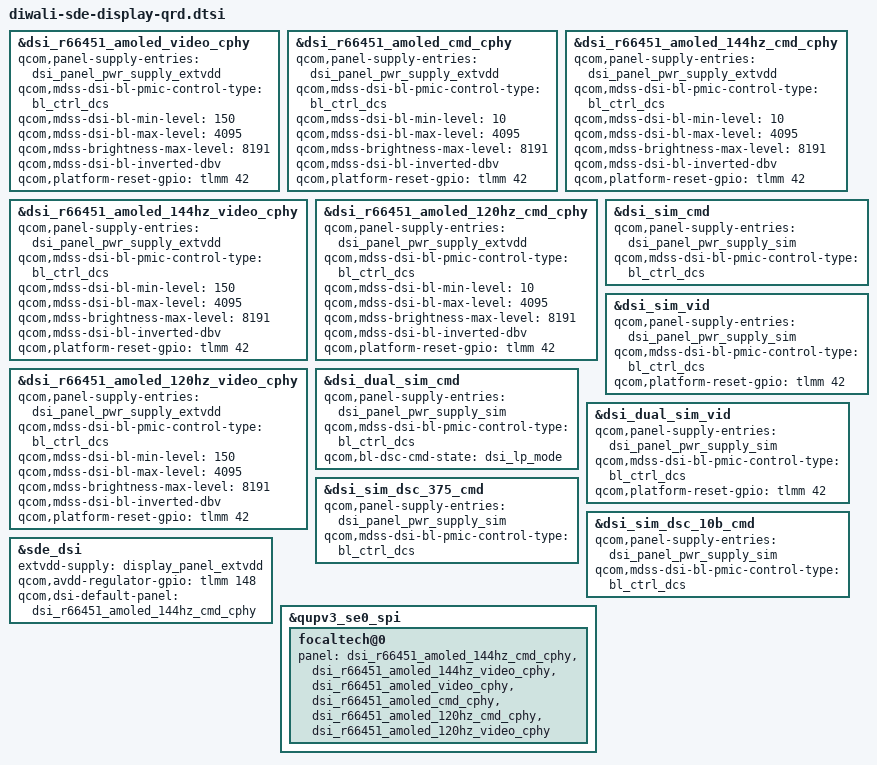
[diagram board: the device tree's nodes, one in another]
#include "diwali-sde-display.dtsi"

&dsi_r66451_amoled_video_cphy {
	qcom,panel-supply-entries = <&dsi_panel_pwr_supply_extvdd>;
	qcom,mdss-dsi-bl-pmic-control-type = "bl_ctrl_dcs";
	qcom,mdss-dsi-bl-min-level = <150>;
	qcom,mdss-dsi-bl-max-level = <4095>;
	qcom,mdss-brightness-max-level = <8191>;
	qcom,mdss-dsi-bl-inverted-dbv;
	qcom,platform-reset-gpio = <&tlmm 42 0>;
};

&dsi_r66451_amoled_cmd_cphy {
	qcom,panel-supply-entries = <&dsi_panel_pwr_supply_extvdd>;
	qcom,mdss-dsi-bl-pmic-control-type = "bl_ctrl_dcs";
	qcom,mdss-dsi-bl-min-level = <10>;
	qcom,mdss-dsi-bl-max-level = <4095>;
	qcom,mdss-brightness-max-level = <8191>;
	qcom,mdss-dsi-bl-inverted-dbv;
	qcom,platform-reset-gpio = <&tlmm 42 0>;
};

&dsi_r66451_amoled_144hz_cmd_cphy {
	qcom,panel-supply-entries = <&dsi_panel_pwr_supply_extvdd>;
	qcom,mdss-dsi-bl-pmic-control-type = "bl_ctrl_dcs";
	qcom,mdss-dsi-bl-min-level = <10>;
	qcom,mdss-dsi-bl-max-level = <4095>;
	qcom,mdss-brightness-max-level = <8191>;
	qcom,mdss-dsi-bl-inverted-dbv;
	qcom,platform-reset-gpio = <&tlmm 42 0>;
};

&dsi_r66451_amoled_144hz_video_cphy {
	qcom,panel-supply-entries = <&dsi_panel_pwr_supply_extvdd>;
	qcom,mdss-dsi-bl-pmic-control-type = "bl_ctrl_dcs";
	qcom,mdss-dsi-bl-min-level = <150>;
	qcom,mdss-dsi-bl-max-level = <4095>;
	qcom,mdss-brightness-max-level = <8191>;
	qcom,mdss-dsi-bl-inverted-dbv;
	qcom,platform-reset-gpio = <&tlmm 42 0>;
};

&dsi_r66451_amoled_120hz_cmd_cphy {
	qcom,panel-supply-entries = <&dsi_panel_pwr_supply_extvdd>;
	qcom,mdss-dsi-bl-pmic-control-type = "bl_ctrl_dcs";
	qcom,mdss-dsi-bl-min-level = <10>;
	qcom,mdss-dsi-bl-max-level = <4095>;
	qcom,mdss-brightness-max-level = <8191>;
	qcom,mdss-dsi-bl-inverted-dbv;
	qcom,platform-reset-gpio = <&tlmm 42 0>;
};

&dsi_r66451_amoled_120hz_video_cphy {
	qcom,panel-supply-entries = <&dsi_panel_pwr_supply_extvdd>;
	qcom,mdss-dsi-bl-pmic-control-type = "bl_ctrl_dcs";
	qcom,mdss-dsi-bl-min-level = <150>;
	qcom,mdss-dsi-bl-max-level = <4095>;
	qcom,mdss-brightness-max-level = <8191>;
	qcom,mdss-dsi-bl-inverted-dbv;
	qcom,platform-reset-gpio = <&tlmm 42 0>;
};

&dsi_sim_cmd {
	qcom,panel-supply-entries = <&dsi_panel_pwr_supply_sim>;
	qcom,mdss-dsi-bl-pmic-control-type = "bl_ctrl_dcs";
};

&dsi_sim_vid {
	qcom,panel-supply-entries = <&dsi_panel_pwr_supply_sim>;
	qcom,mdss-dsi-bl-pmic-control-type = "bl_ctrl_dcs";
	qcom,platform-reset-gpio = <&tlmm 42 0>;
};

&dsi_dual_sim_cmd {
	qcom,panel-supply-entries = <&dsi_panel_pwr_supply_sim>;
	qcom,mdss-dsi-bl-pmic-control-type = "bl_ctrl_dcs";
	qcom,bl-dsc-cmd-state = "dsi_lp_mode";
};

&dsi_dual_sim_vid {
	qcom,panel-supply-entries = <&dsi_panel_pwr_supply_sim>;
	qcom,mdss-dsi-bl-pmic-control-type = "bl_ctrl_dcs";
	qcom,platform-reset-gpio = <&tlmm 42 0>;
};

&dsi_sim_dsc_375_cmd {
	qcom,panel-supply-entries = <&dsi_panel_pwr_supply_sim>;
	qcom,mdss-dsi-bl-pmic-control-type = "bl_ctrl_dcs";
};

&dsi_sim_dsc_10b_cmd {
	qcom,panel-supply-entries = <&dsi_panel_pwr_supply_sim>;
	qcom,mdss-dsi-bl-pmic-control-type = "bl_ctrl_dcs";
};

&sde_dsi {
	extvdd-supply = <&display_panel_extvdd>;
	qcom,avdd-regulator-gpio = <&tlmm 148 0>;
	qcom,dsi-default-panel = <&dsi_r66451_amoled_144hz_cmd_cphy>;
};

&qupv3_se0_spi {
	focaltech@0 {
		panel = <&dsi_r66451_amoled_144hz_cmd_cphy
			&dsi_r66451_amoled_144hz_video_cphy
			&dsi_r66451_amoled_video_cphy
			&dsi_r66451_amoled_cmd_cphy
			&dsi_r66451_amoled_120hz_cmd_cphy
			&dsi_r66451_amoled_120hz_video_cphy>;
	};
};
